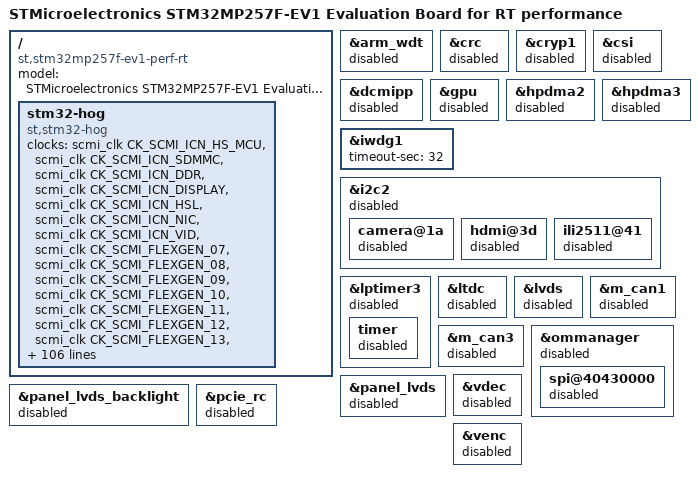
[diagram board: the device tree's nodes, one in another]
// SPDX-License-Identifier: (GPL-2.0-or-later OR BSD-3-Clause)
/*
 * Copyright (C) STMicroelectronics 2024 - All Rights Reserved
 * Author: Gatien Chevallier <gatien.chevallier@foss.st.com> for STMicroelectronics.
 */

#include <stm32mp257f-ev1.dts>

/ {
	model = "STMicroelectronics STM32MP257F-EV1 Evaluation Board for RT performance";
	compatible = "st,stm32mp257f-ev1-perf-rt", "st,stm32mp257f-ev1-rt", "st,stm32mp257f-ev1", "st,stm32mp257";

	stm32-hog {
		compatible = "st,stm32-hog";
		clocks	=	<&scmi_clk CK_SCMI_ICN_HS_MCU>,
				<&scmi_clk CK_SCMI_ICN_SDMMC>,
				<&scmi_clk CK_SCMI_ICN_DDR>,
				<&scmi_clk CK_SCMI_ICN_DISPLAY>,
				<&scmi_clk CK_SCMI_ICN_HSL>,
				<&scmi_clk CK_SCMI_ICN_NIC>,
				<&scmi_clk CK_SCMI_ICN_VID>,
				<&scmi_clk CK_SCMI_FLEXGEN_07>,
				<&scmi_clk CK_SCMI_FLEXGEN_08>,
				<&scmi_clk CK_SCMI_FLEXGEN_09>,
				<&scmi_clk CK_SCMI_FLEXGEN_10>,
				<&scmi_clk CK_SCMI_FLEXGEN_11>,
				<&scmi_clk CK_SCMI_FLEXGEN_12>,
				<&scmi_clk CK_SCMI_FLEXGEN_13>,
				<&scmi_clk CK_SCMI_FLEXGEN_14>,
				<&scmi_clk CK_SCMI_FLEXGEN_15>,
				<&scmi_clk CK_SCMI_FLEXGEN_16>,
				<&scmi_clk CK_SCMI_FLEXGEN_17>,
				<&scmi_clk CK_SCMI_FLEXGEN_18>,
				<&scmi_clk CK_SCMI_FLEXGEN_19>,
				<&scmi_clk CK_SCMI_FLEXGEN_20>,
				<&scmi_clk CK_SCMI_FLEXGEN_21>,
				<&scmi_clk CK_SCMI_FLEXGEN_22>,
				<&scmi_clk CK_SCMI_FLEXGEN_23>,
				<&scmi_clk CK_SCMI_FLEXGEN_24>,
				<&scmi_clk CK_SCMI_FLEXGEN_25>,
				<&scmi_clk CK_SCMI_FLEXGEN_26>,
				<&scmi_clk CK_SCMI_FLEXGEN_27>,
				<&scmi_clk CK_SCMI_FLEXGEN_28>,
				<&scmi_clk CK_SCMI_FLEXGEN_29>,
				<&scmi_clk CK_SCMI_FLEXGEN_30>,
				<&scmi_clk CK_SCMI_FLEXGEN_31>,
				<&scmi_clk CK_SCMI_FLEXGEN_32>,
				<&scmi_clk CK_SCMI_FLEXGEN_33>,
				<&scmi_clk CK_SCMI_FLEXGEN_34>,
				<&scmi_clk CK_SCMI_FLEXGEN_35>,
				<&scmi_clk CK_SCMI_FLEXGEN_36>,
				<&scmi_clk CK_SCMI_FLEXGEN_37>,
				<&scmi_clk CK_SCMI_FLEXGEN_38>,
				<&scmi_clk CK_SCMI_FLEXGEN_39>,
				<&scmi_clk CK_SCMI_FLEXGEN_40>,
				<&scmi_clk CK_SCMI_FLEXGEN_41>,
				<&scmi_clk CK_SCMI_FLEXGEN_42>,
				<&scmi_clk CK_SCMI_FLEXGEN_43>,
				<&scmi_clk CK_SCMI_FLEXGEN_44>,
				<&scmi_clk CK_SCMI_FLEXGEN_45>,
				<&scmi_clk CK_SCMI_FLEXGEN_46>,
				<&scmi_clk CK_SCMI_FLEXGEN_47>,
				<&scmi_clk CK_SCMI_FLEXGEN_48>,
				<&scmi_clk CK_SCMI_FLEXGEN_49>,
				<&scmi_clk CK_SCMI_FLEXGEN_50>,
				<&scmi_clk CK_SCMI_FLEXGEN_51>,
				<&scmi_clk CK_SCMI_FLEXGEN_52>,
				<&scmi_clk CK_SCMI_FLEXGEN_53>,
				<&scmi_clk CK_SCMI_FLEXGEN_54>,
				<&scmi_clk CK_SCMI_FLEXGEN_55>,
				<&scmi_clk CK_SCMI_FLEXGEN_56>,
				<&scmi_clk CK_SCMI_FLEXGEN_57>,
				<&scmi_clk CK_SCMI_FLEXGEN_58>,
				<&scmi_clk CK_SCMI_FLEXGEN_59>,
				<&scmi_clk CK_SCMI_FLEXGEN_60>,
				<&scmi_clk CK_SCMI_FLEXGEN_61>,
				<&scmi_clk CK_SCMI_FLEXGEN_62>,
				<&scmi_clk CK_SCMI_FLEXGEN_63>,
				<&scmi_clk CK_SCMI_ICN_LS_MCU>,
				<&scmi_clk CK_SCMI_HSE>,
				<&scmi_clk CK_SCMI_LSE>,
				<&scmi_clk CK_SCMI_HSI>,
				<&scmi_clk CK_SCMI_LSI>,
				<&scmi_clk CK_SCMI_MSI>,
				<&scmi_clk CK_SCMI_HSE_DIV2>,
				<&scmi_clk CK_SCMI_CPU1>,
				<&scmi_clk CK_SCMI_SYSCPU1>,
				<&scmi_clk CK_SCMI_RTC>,
				<&scmi_clk CK_SCMI_RTCCK>,
				<&scmi_clk CK_SCMI_ICN_APB1>,
				<&scmi_clk CK_SCMI_ICN_APB2>,
				<&scmi_clk CK_SCMI_ICN_APB3>,
				<&scmi_clk CK_SCMI_ICN_APB4>,
				<&scmi_clk CK_SCMI_ICN_APBDBG>,
				<&scmi_clk CK_SCMI_TIMG1>,
				<&scmi_clk CK_SCMI_TIMG2>,
				<&scmi_clk CK_SCMI_BKPSRAM>,
				<&scmi_clk CK_SCMI_BSEC>,
				<&scmi_clk CK_SCMI_BUS_ETR>,
				<&scmi_clk CK_SCMI_FMC>,
				<&scmi_clk CK_SCMI_GPIOA>,
				<&scmi_clk CK_SCMI_GPIOB>,
				<&scmi_clk CK_SCMI_GPIOC>,
				<&scmi_clk CK_SCMI_GPIOD>,
				<&scmi_clk CK_SCMI_GPIOE>,
				<&scmi_clk CK_SCMI_GPIOF>,
				<&scmi_clk CK_SCMI_GPIOG>,
				<&scmi_clk CK_SCMI_GPIOH>,
				<&scmi_clk CK_SCMI_GPIOI>,
				<&scmi_clk CK_SCMI_GPIOJ>,
				<&scmi_clk CK_SCMI_GPIOK>,
				<&scmi_clk CK_SCMI_GPIOZ>,
				<&scmi_clk CK_SCMI_HPDMA1>,
				<&scmi_clk CK_SCMI_HPDMA2>,
				<&scmi_clk CK_SCMI_HPDMA3>,
				<&scmi_clk CK_SCMI_HSEM>,
				<&scmi_clk CK_SCMI_IPCC1>,
				<&scmi_clk CK_SCMI_IPCC2>,
				<&scmi_clk CK_SCMI_LPDMA>,
				<&scmi_clk CK_SCMI_RETRAM>,
				<&scmi_clk CK_SCMI_SRAM1>,
				<&scmi_clk CK_SCMI_SRAM2>,
				<&scmi_clk CK_SCMI_LPSRAM1>,
				<&scmi_clk CK_SCMI_LPSRAM2>,
				<&scmi_clk CK_SCMI_LPSRAM3>,
				<&scmi_clk CK_SCMI_VDERAM>,
				<&scmi_clk CK_SCMI_SYSRAM>,
				<&scmi_clk CK_SCMI_OSPI1>,
				<&scmi_clk CK_SCMI_OSPI2>,
				<&scmi_clk CK_SCMI_TPIU>,
				<&scmi_clk CK_SCMI_SYSDBG>,
				<&scmi_clk CK_SCMI_SYSATB>,
				<&scmi_clk CK_SCMI_TSDBG>,
				<&scmi_clk CK_SCMI_BUS_STM>,
				<&scmi_clk CK_SCMI_KER_STM>,
				<&scmi_clk CK_SCMI_KER_ETR>;
		status = "okay";
	};
};


&arm_wdt {
	status = "disabled";
};

&crc {
	status = "disabled";
};

&cryp1 {
	status = "disabled";
};

&csi{
	status = "disabled";
};

&dcmipp{
	status = "disabled";
};

&gpu{
	status = "disabled";
};

&hpdma2 {
	status = "disabled";
};

&hpdma3 {
	status = "disabled";
};

&iwdg1 {
	timeout-sec = <32>;
	status = "okay";
};

&i2c2 {
	status = "disabled";
	camera@1a {
		status = "disabled";
	};
	hdmi@3d {
		status = "disabled";
	};
	ili2511@41 {
		status = "disabled";
	};
};

&lptimer3 {
	status = "disabled";
	timer {
		status = "disabled";
	};
};

&ltdc{
	status = "disabled";
};

&lvds{
	status = "disabled";
};

&m_can1 {
	status = "disabled";
};

&m_can3{
	status = "disabled";
};

&ommanager {
	status = "disabled";
	spi@40430000 {
		status = "disabled";
	};
};

&panel_lvds {
	status = "disabled";
};

&panel_lvds_backlight {
	status = "disabled";
};

&pcie_rc {
	status = "disabled";
};

&vdec {
	status = "disabled";
};

&venc {
	status = "disabled";
};
